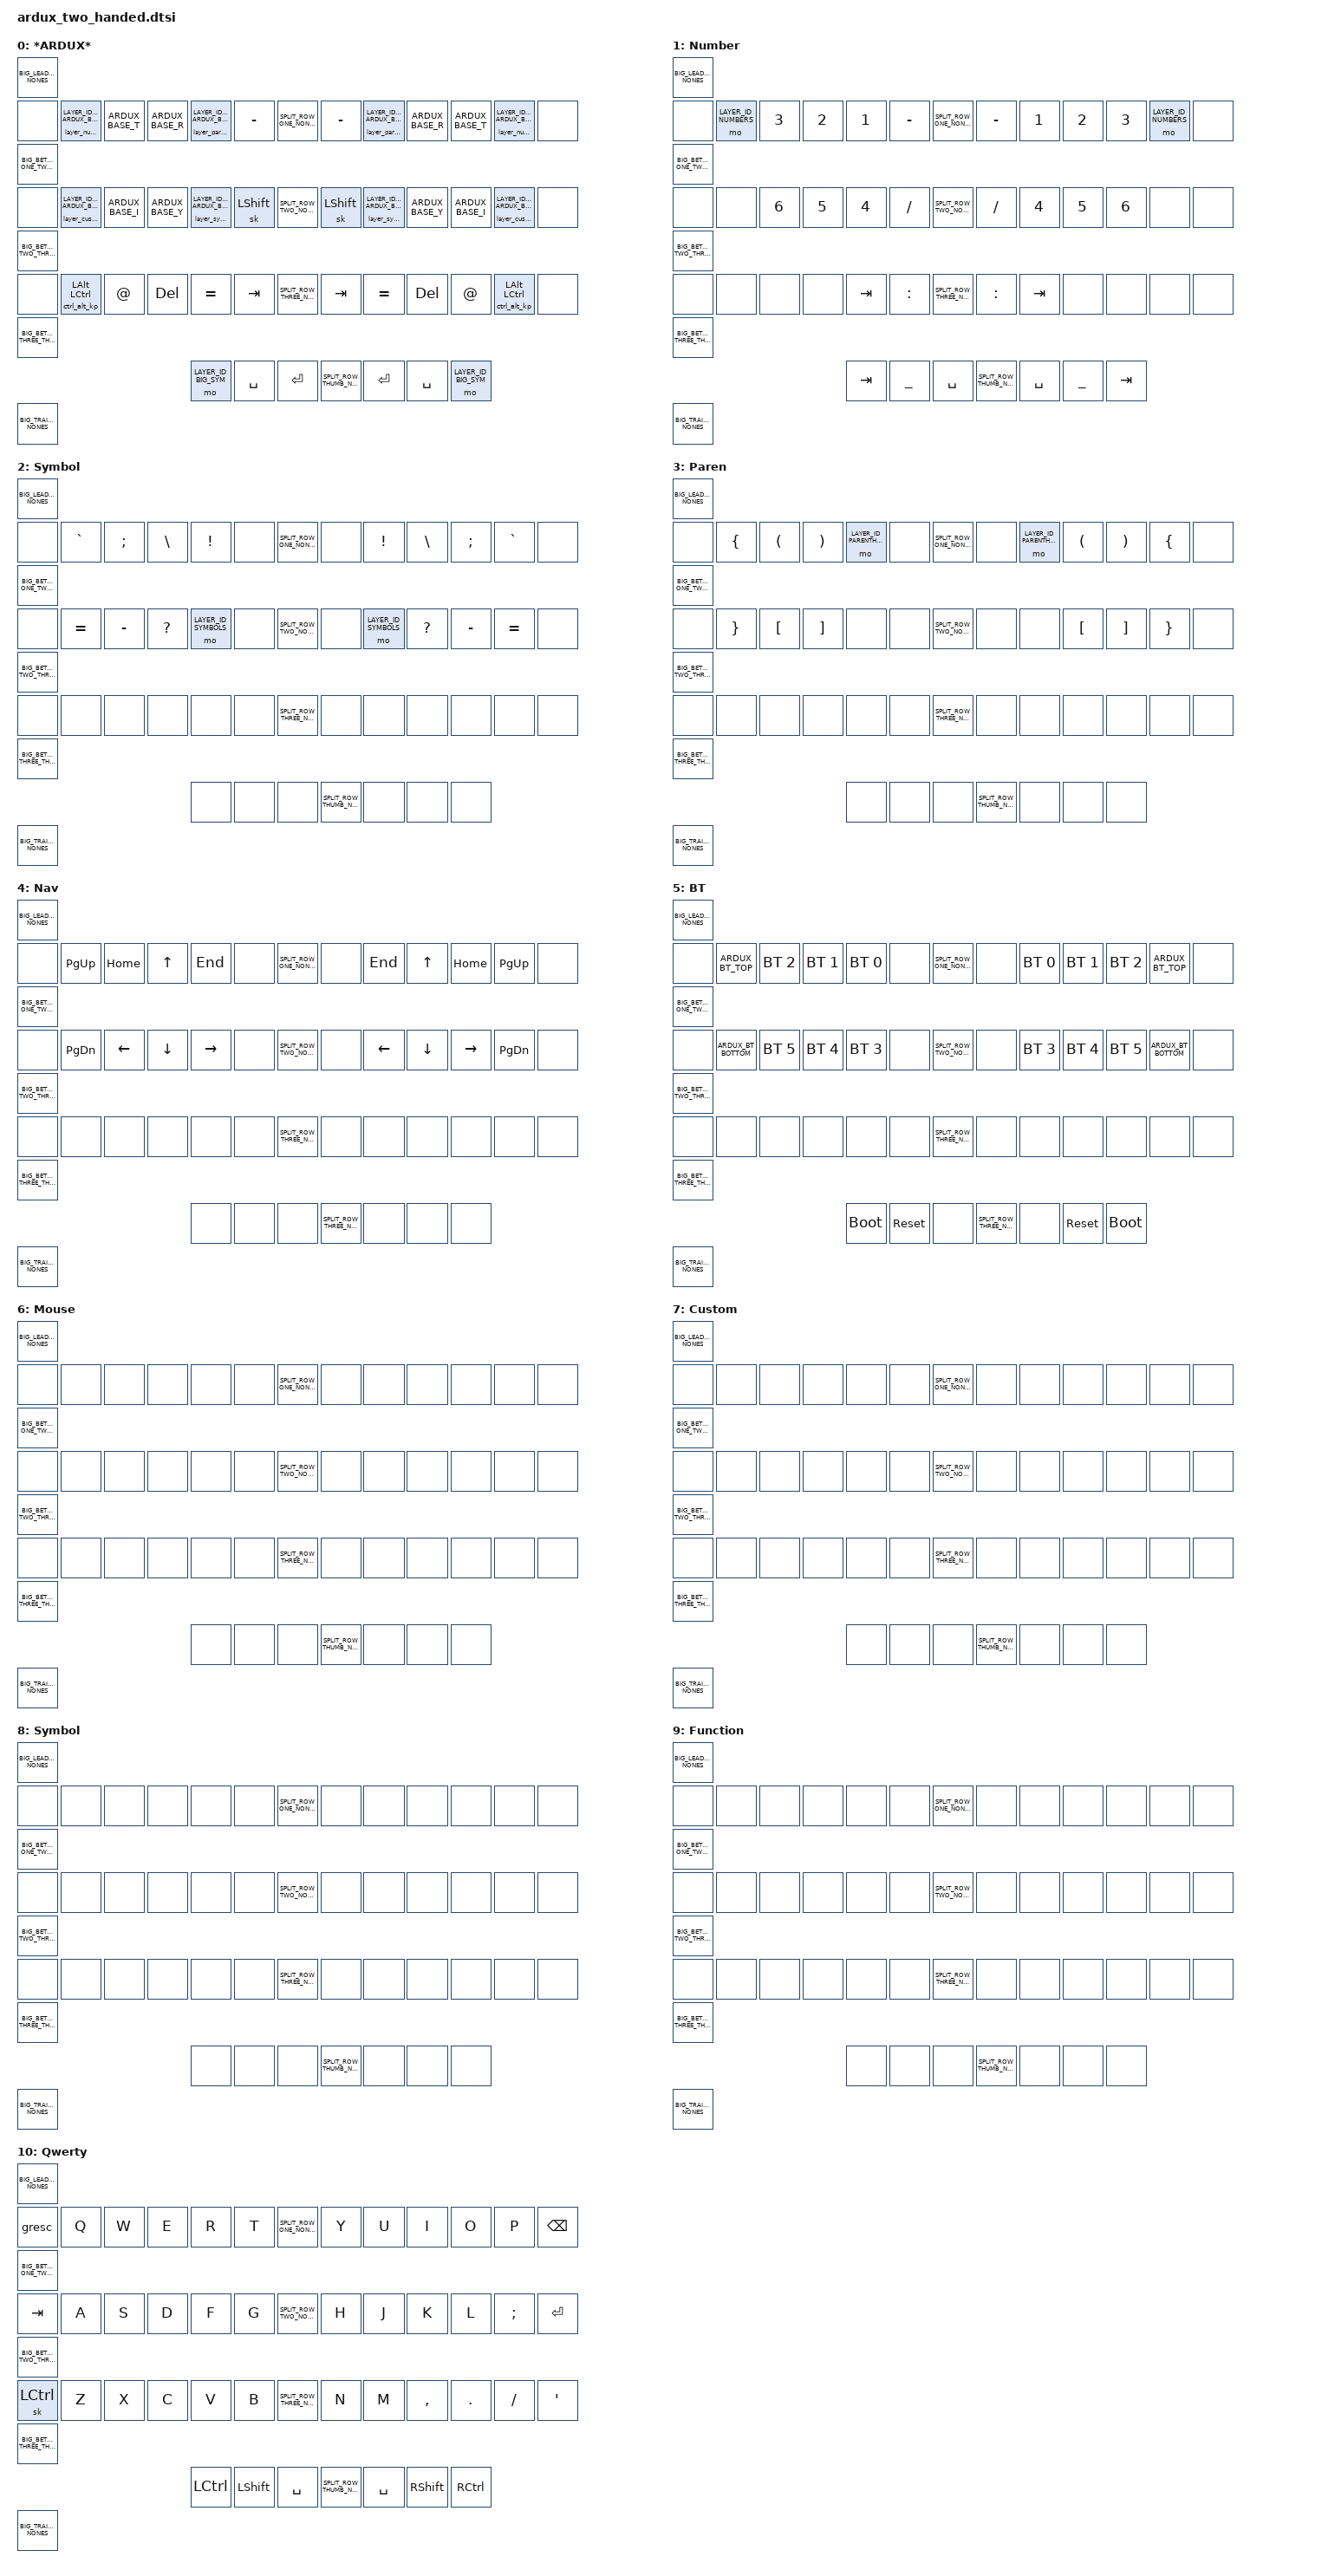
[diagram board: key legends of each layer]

#define USE_SPLIT_COMBOS 1

#include "combos.dtsi"

/*****************************************
 * ARDUX website : https://www.ardux.io
 * Primary reference : https://www.ardux.io/_FILES/images/ARDUX.jpg
*****************************************/

/*****************************************
 * Standard ARDUX layer definitions
 *****************************************/
/ {
	keymap {
		compatible = "zmk,keymap";
		base {
			display-name = "*ARDUX*";
			bindings = <
				BIG_LEADING_NONES
				&none	&layer_numbers_kp LAYER_ID_NUMBERS ARDUX_BASE_S			&kp ARDUX_BASE_T		&kp ARDUX_BASE_R	&layer_parentheticals_kp LAYER_ID_PARENTHETICALS ARDUX_BASE_A	&kp MINUS	SPLIT_ROW_ONE_NONES		&kp MINUS	&layer_parentheticals_kp LAYER_ID_PARENTHETICALS ARDUX_BASE_A	&kp ARDUX_BASE_R   	&kp ARDUX_BASE_T	&layer_numbers_kp LAYER_ID_NUMBERS ARDUX_BASE_S	&none
				BIG_BETWEEN_ROW_ONE_TWO_NONES
				&none	&layer_custom_kp LAYER_ID_CUSTOM ARDUX_BASE_O			&kp ARDUX_BASE_I		&kp ARDUX_BASE_Y	&layer_symbols_kp LAYER_ID_SYMBOLS ARDUX_BASE_E					&sk LSHFT	SPLIT_ROW_TWO_NONES		&sk LSHFT	&layer_symbols_kp LAYER_ID_SYMBOLS ARDUX_BASE_E					&kp ARDUX_BASE_Y	&kp ARDUX_BASE_I	&layer_custom_kp LAYER_ID_CUSTOM ARDUX_BASE_O 	&none
				BIG_BETWEEN_ROW_TWO_THREE_NONES
				&none	&ctrl_alt_kp LALT LCTRL									&kp AT					&kp DEL				&kp EQUAL														&kp TAB		SPLIT_ROW_THREE_NONES	&kp TAB		&kp EQUAL                                                		&kp DEL				&kp AT				&ctrl_alt_kp LALT LCTRL							&none
				BIG_BETWEEN_ROW_THREE_THUMBS
																																						&mo LAYER_ID_BIG_SYM	&kp SPACE	&kp ENTER	SPLIT_ROW_THUMB_NONES	&kp ENTER	&kp SPACE	&mo LAYER_ID_BIG_SYM
				BIG_TRAILING_NONES
			>;
		};
		numbers {
			display-name = "Number";
			bindings = <
				BIG_LEADING_NONES
				&none	&mo LAYER_ID_NUMBERS	&kp N3	&kp N2	&kp N1			&kp MINUS	SPLIT_ROW_ONE_NONES		&kp MINUS	&kp N1			&kp N2	&kp N3	&mo LAYER_ID_NUMBERS	&none
				BIG_BETWEEN_ROW_ONE_TWO_NONES
				&none	&none					&kp N6	&kp N5	&kp N4			&kp SLASH	SPLIT_ROW_TWO_NONES		&kp SLASH	&kp N4			&kp N5	&kp N6	&none					&none
				BIG_BETWEEN_ROW_TWO_THREE_NONES
				&none	&none					&none	&none	&kp TAB			&kp COLON	SPLIT_ROW_THREE_NONES	&kp COLON	&kp TAB			&none	&none	&none					&none
				BIG_BETWEEN_ROW_THREE_THUMBS
														&kp TAB	&kp UNDERSCORE	&kp SPACE	SPLIT_ROW_THUMB_NONES	&kp SPACE	&kp UNDERSCORE	&kp TAB
				BIG_TRAILING_NONES
			>;
		};
		symbols {
			display-name = "Symbol";
			bindings = <
				BIG_LEADING_NONES
				&none	&kp GRAVE	&kp SEMI	&kp BSLH	&kp EXCL				&none	SPLIT_ROW_ONE_NONES		&none	&kp EXCL				&kp BSLH	&kp SEMI	&kp GRAVE	&none
				BIG_BETWEEN_ROW_ONE_TWO_NONES
				&none	&kp EQUAL	&kp MINUS	&kp QMARK	&mo LAYER_ID_SYMBOLS	&none	SPLIT_ROW_TWO_NONES		&none	&mo LAYER_ID_SYMBOLS	&kp QMARK	&kp MINUS	&kp EQUAL	&none
				BIG_BETWEEN_ROW_TWO_THREE_NONES
				&none	&none		&none		&none		&none					&none	SPLIT_ROW_THREE_NONES	&none	&none					&none		&none		&none		&none
				BIG_BETWEEN_ROW_THREE_THUMBS
												&none		&none					&none	SPLIT_ROW_THUMB_NONES	&none	&none					&none
				BIG_TRAILING_NONES
			>;
		};
		parentheticals {
			display-name = "Paren";
			bindings = <
				BIG_LEADING_NONES
				&none	&kp LBRC	&kp LPAR	&kp RPAR	&mo LAYER_ID_PARENTHETICALS	&none	SPLIT_ROW_ONE_NONES		&none	&mo LAYER_ID_PARENTHETICALS	&kp LPAR	&kp RPAR	&kp LBRC	&none
				BIG_BETWEEN_ROW_ONE_TWO_NONES
				&none	&kp RBRC	&kp LBKT	&kp RBKT	&none						&none	SPLIT_ROW_TWO_NONES		&none	&none						&kp LBKT	&kp RBKT	&kp RBRC	&none
				BIG_BETWEEN_ROW_TWO_THREE_NONES
				&none	&none		&none		&none		&none						&none	SPLIT_ROW_THREE_NONES	&none	&none						&none		&none		&none		&none
				BIG_BETWEEN_ROW_THREE_THUMBS
												&none		&none						&none	SPLIT_ROW_THUMB_NONES	&none	&none						&none
				BIG_TRAILING_NONES
			>;
		};
		navigation {
			display-name = "Nav";
			bindings = <
				BIG_LEADING_NONES
				&none	&kp PG_UP	&kp HOME	&kp UP		&kp END		&none	SPLIT_ROW_ONE_NONES		&none	&kp END		&kp UP		&kp HOME	&kp PG_UP	&none
				BIG_BETWEEN_ROW_ONE_TWO_NONES
				&none	&kp PG_DN	&kp LEFT	&kp DOWN	&kp RIGHT	&none	SPLIT_ROW_TWO_NONES		&none	&kp LEFT	&kp DOWN	&kp RIGHT	&kp PG_DN	&none
				BIG_BETWEEN_ROW_TWO_THREE_NONES
				&none	&none		&none		&none		&none		&none	SPLIT_ROW_THREE_NONES	&none	&none		&none		&none		&none		&none
				BIG_BETWEEN_ROW_THREE_THUMBS
												&none		&none		&none	SPLIT_ROW_THREE_NONES	&none	&none		&none
				BIG_TRAILING_NONES
			>;
		};
		bt {
			display-name = "BT";
			bindings = <
				BIG_LEADING_NONES
				&none	ARDUX_BT_TOP	&bt BT_SEL 2	&bt BT_SEL 1	&bt BT_SEL 0	&none	SPLIT_ROW_ONE_NONES		&none	&bt BT_SEL 0	&bt BT_SEL 1	&bt BT_SEL 2	ARDUX_BT_TOP	&none
				BIG_BETWEEN_ROW_ONE_TWO_NONES
				&none	ARDUX_BT_BOTTOM	&bt BT_SEL 5	&bt BT_SEL 4	&bt BT_SEL 3	&none	SPLIT_ROW_TWO_NONES		&none	&bt BT_SEL 3	&bt BT_SEL 4	&bt BT_SEL 5	ARDUX_BT_BOTTOM	&none
				BIG_BETWEEN_ROW_TWO_THREE_NONES
				&none	&none			&none			&none			&none			&none	SPLIT_ROW_THREE_NONES	&none	&none			&none			&none			&none			&none
				BIG_BETWEEN_ROW_THREE_THUMBS
														&bootloader		&sys_reset		&none	SPLIT_ROW_THREE_NONES	&none	&sys_reset		&bootloader
				BIG_TRAILING_NONES
			>;
		};
		// TODO
		mouse {
			display-name = "Mouse";
			bindings = <
				BIG_LEADING_NONES
				&none	&none	&none	&none	&none	&none	SPLIT_ROW_ONE_NONES		&none	&none	&none	&none	&none	&none
				BIG_BETWEEN_ROW_ONE_TWO_NONES
				&none	&none	&none	&none	&none	&none	SPLIT_ROW_TWO_NONES		&none	&none	&none	&none	&none	&none
				BIG_BETWEEN_ROW_TWO_THREE_NONES
				&none	&none	&none	&none	&none	&none	SPLIT_ROW_THREE_NONES	&none	&none	&none	&none	&none	&none
				BIG_BETWEEN_ROW_THREE_THUMBS
										&none	&none	&none	SPLIT_ROW_THUMB_NONES	&none	&none	&none
				BIG_TRAILING_NONES
			>;
		};
		// TODO
		custom {
			display-name = "Custom";
			bindings = <
				BIG_LEADING_NONES
				&none	&none	&none	&none	&none	&none	SPLIT_ROW_ONE_NONES		&none	&none	&none	&none	&none	&none
				BIG_BETWEEN_ROW_ONE_TWO_NONES
				&none	&none	&none	&none	&none	&none	SPLIT_ROW_TWO_NONES		&none	&none	&none	&none	&none	&none
				BIG_BETWEEN_ROW_TWO_THREE_NONES
				&none	&none	&none	&none	&none	&none	SPLIT_ROW_THREE_NONES	&none	&none	&none	&none	&none	&none
				BIG_BETWEEN_ROW_THREE_THUMBS
										&none	&none	&none	SPLIT_ROW_THUMB_NONES	&none	&none	&none
				BIG_TRAILING_NONES
			>;
		};
		// TODO
		big_sym {
			display-name = "Symbol";
			bindings = <
				BIG_LEADING_NONES
				&none	&none	&none	&none	&none	&none	SPLIT_ROW_ONE_NONES		&none	&none	&none	&none	&none	&none
				BIG_BETWEEN_ROW_ONE_TWO_NONES
				&none	&none	&none	&none	&none	&none	SPLIT_ROW_TWO_NONES		&none	&none	&none	&none	&none	&none
				BIG_BETWEEN_ROW_TWO_THREE_NONES
				&none	&none	&none	&none	&none	&none	SPLIT_ROW_THREE_NONES	&none	&none	&none	&none	&none	&none
				BIG_BETWEEN_ROW_THREE_THUMBS
										&none	&none	&none	SPLIT_ROW_THUMB_NONES	&none	&none	&none
				BIG_TRAILING_NONES
			>;
		};
		// TODO
		big_function {
			display-name = "Function";
			bindings = <
				BIG_LEADING_NONES
				&none	&none	&none	&none	&none	&none	SPLIT_ROW_ONE_NONES		&none	&none	&none	&none	&none	&none
				BIG_BETWEEN_ROW_ONE_TWO_NONES
				&none	&none	&none	&none	&none	&none	SPLIT_ROW_TWO_NONES		&none	&none	&none	&none	&none	&none
				BIG_BETWEEN_ROW_TWO_THREE_NONES
				&none	&none	&none	&none	&none	&none	SPLIT_ROW_THREE_NONES	&none	&none	&none	&none	&none	&none
				BIG_BETWEEN_ROW_THREE_THUMBS
										&none	&none	&none	SPLIT_ROW_THUMB_NONES	&none	&none	&none
				BIG_TRAILING_NONES
			>;
		};
		qwerty {
			display-name = "Qwerty";
			bindings = <
				BIG_LEADING_NONES
				&gresc		&kp Q	&kp W	&kp E		&kp R		&kp T		SPLIT_ROW_ONE_NONES		&kp Y		&kp U		&kp I		&kp O		&kp P		&kp BACKSPACE
				BIG_BETWEEN_ROW_ONE_TWO_NONES
				&kp TAB		&kp A	&kp S	&kp D		&kp F		&kp G		SPLIT_ROW_TWO_NONES		&kp H		&kp J		&kp K		&kp L		&kp SEMI	&kp ENTER
				BIG_BETWEEN_ROW_TWO_THREE_NONES
				&sk LCTRL	&kp Z	&kp X	&kp C		&kp V		&kp B		SPLIT_ROW_THREE_NONES	&kp N		&kp M		&kp COMMA	&kp PERIOD	&kp SLASH	&kp SQT
				BIG_BETWEEN_ROW_THREE_THUMBS
											&kp LCTRL	&kp LSHIFT	&kp SPACE	SPLIT_ROW_THUMB_NONES	&kp SPACE	&kp RSHIFT	&kp RCTRL
				BIG_TRAILING_NONES
			>;
		};
	};
};
